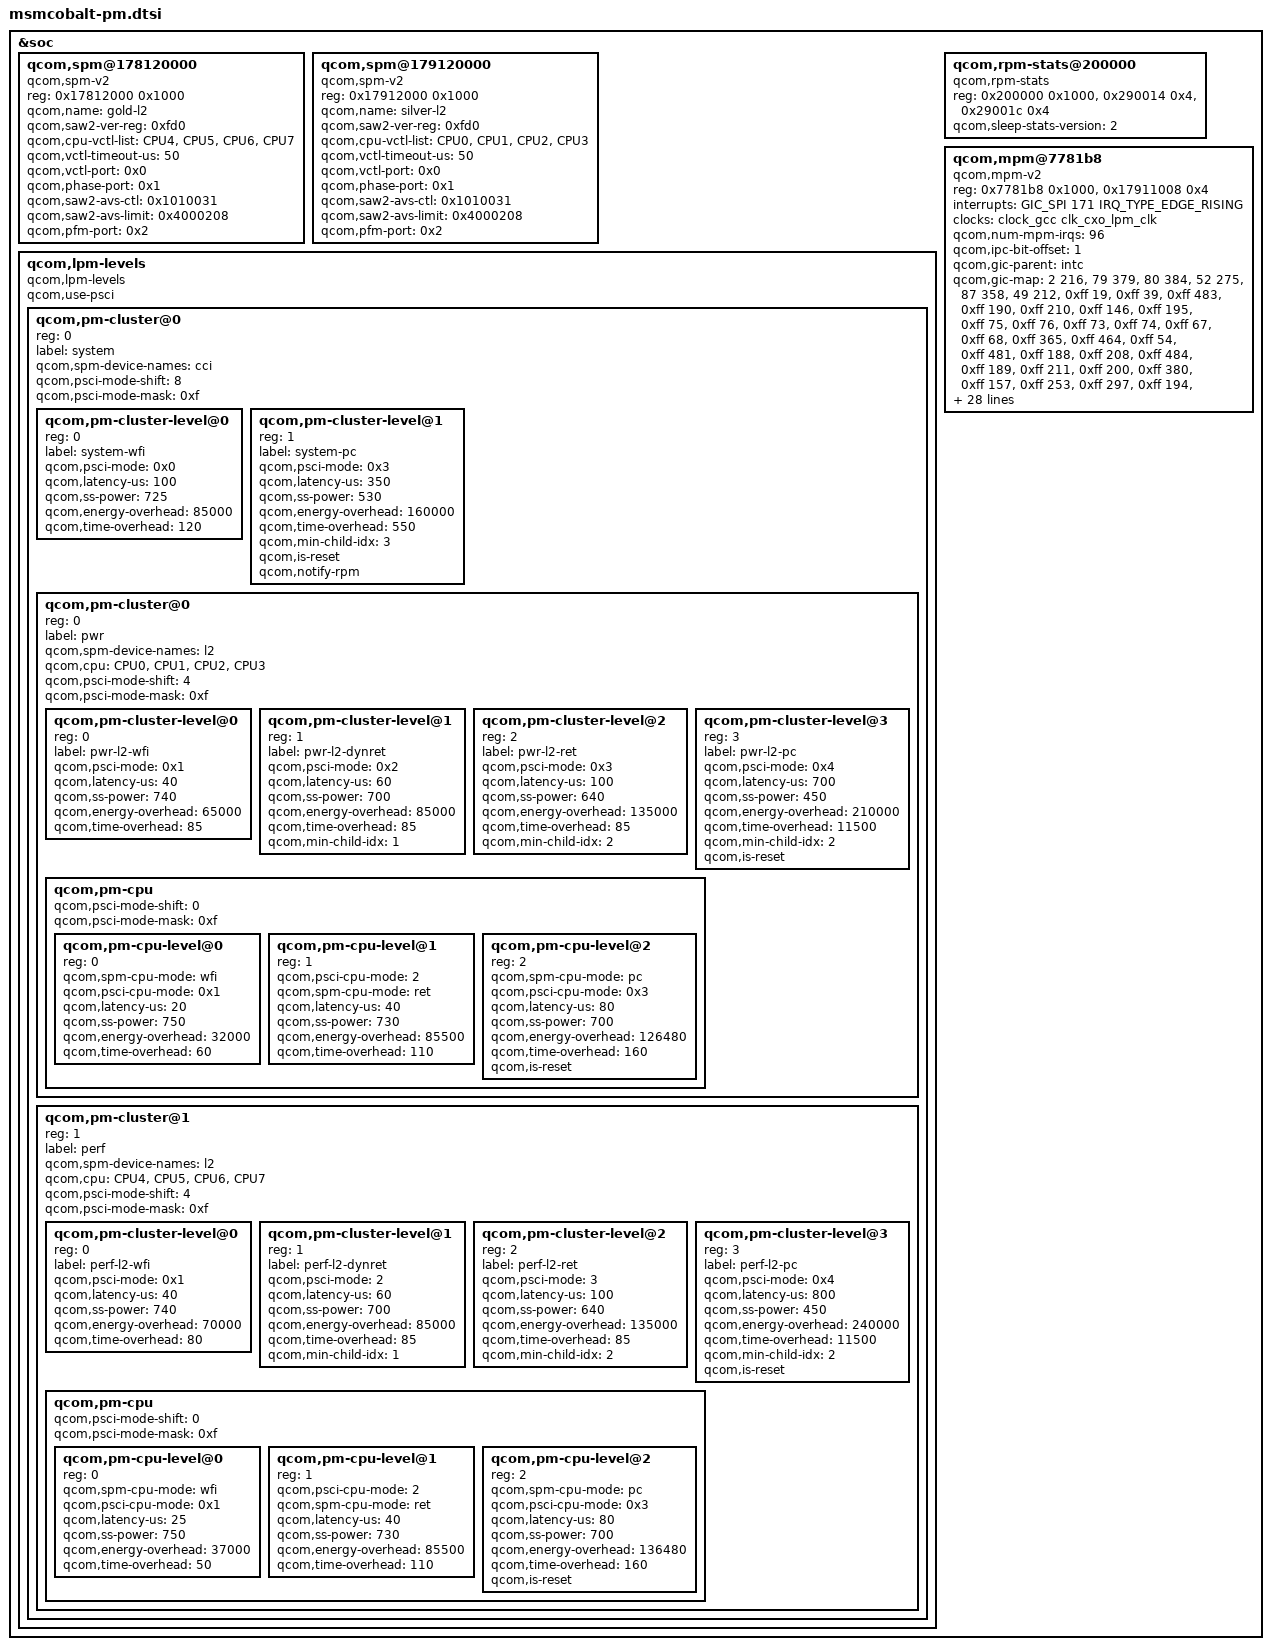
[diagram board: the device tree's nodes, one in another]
/* Copyright (c) 2016, The Linux Foundation. All rights reserved.
 *
 * This program is free software; you can redistribute it and/or modify
 * it under the terms of the GNU General Public License version 2 and
 * only version 2 as published by the Free Software Foundation.
 *
 * This program is distributed in the hope that it will be useful,
 * but WITHOUT ANY WARRANTY; without even the implied warranty of
 * MERCHANTABILITY or FITNESS FOR A PARTICULAR PURPOSE.  See the
 * GNU General Public License for more details.
 */
#include <dt-bindings/interrupt-controller/arm-gic.h>

&soc {
	qcom,spm@178120000 {
		compatible = "qcom,spm-v2";
		#address-cells = <1>;
		#size-cells = <1>;
		reg = <0x17812000 0x1000>;
		qcom,name = "gold-l2"; /* Gold L2 SAW */
		qcom,saw2-ver-reg = <0xfd0>;
		qcom,cpu-vctl-list = <&CPU4 &CPU5 &CPU6 &CPU7>;
		qcom,vctl-timeout-us = <50>;
		qcom,vctl-port = <0x0>;
		qcom,phase-port = <0x1>;
		qcom,saw2-avs-ctl = <0x1010031>;
		qcom,saw2-avs-limit = <0x4000208>;
		qcom,pfm-port = <0x2>;
	};

	qcom,spm@179120000 {
		compatible = "qcom,spm-v2";
		#address-cells = <1>;
		#size-cells = <1>;
		reg = <0x17912000 0x1000>;
		qcom,name = "silver-l2"; /* Silver L2 SAW */
		qcom,saw2-ver-reg = <0xfd0>;
		qcom,cpu-vctl-list = <&CPU0 &CPU1 &CPU2 &CPU3>;
		qcom,vctl-timeout-us = <50>;
		qcom,vctl-port = <0x0>;
		qcom,phase-port = <0x1>;
		qcom,saw2-avs-ctl = <0x1010031>;
		qcom,saw2-avs-limit = <0x4000208>;
		qcom,pfm-port = <0x2>;
	};

	qcom,lpm-levels {
		compatible = "qcom,lpm-levels";
		qcom,use-psci;
		#address-cells = <1>;
		#size-cells = <0>;
		qcom,pm-cluster@0 {
			reg = <0>;
			#address-cells = <1>;
			#size-cells = <0>;
			label = "system";
			qcom,spm-device-names = "cci";
			qcom,psci-mode-shift = <8>;
			qcom,psci-mode-mask = <0xf>;

			qcom,pm-cluster-level@0{
				reg = <0>;
				label = "system-wfi";
				qcom,psci-mode = <0x0>;
				qcom,latency-us = <100>;
				qcom,ss-power = <725>;
				qcom,energy-overhead = <85000>;
				qcom,time-overhead = <120>;
			};

			qcom,pm-cluster-level@1{ /* E3 */
				reg = <1>;
				label = "system-pc";
				qcom,psci-mode = <0x3>;
				qcom,latency-us = <350>;
				qcom,ss-power = <530>;
				qcom,energy-overhead = <160000>;
				qcom,time-overhead = <550>;
				qcom,min-child-idx = <3>;
				qcom,is-reset;
				qcom,notify-rpm;
			};

			qcom,pm-cluster@0{
				reg = <0>;
				#address-cells = <1>;
				#size-cells = <0>;
				label = "pwr";
				qcom,spm-device-names = "l2";
				qcom,cpu = <&CPU0 &CPU1 &CPU2 &CPU3>;
				qcom,psci-mode-shift = <4>;
				qcom,psci-mode-mask = <0xf>;

				qcom,pm-cluster-level@0{ /* D1 */
					reg = <0>;
					label = "pwr-l2-wfi";
					qcom,psci-mode = <0x1>;
					qcom,latency-us = <40>;
					qcom,ss-power = <740>;
					qcom,energy-overhead = <65000>;
					qcom,time-overhead = <85>;
				};
				qcom,pm-cluster-level@1{ /* D2D */
					reg = <1>;
					label = "pwr-l2-dynret";
					qcom,psci-mode = <0x2>;
					qcom,latency-us = <60>;
					qcom,ss-power = <700>;
					qcom,energy-overhead = <85000>;
					qcom,time-overhead = <85>;
					qcom,min-child-idx = <1>;
				};

				qcom,pm-cluster-level@2{ /* D2E */
					reg = <2>;
					label = "pwr-l2-ret";
					qcom,psci-mode = <0x3>;
					qcom,latency-us = <100>;
					qcom,ss-power = <640>;
					qcom,energy-overhead = <135000>;
					qcom,time-overhead = <85>;
					qcom,min-child-idx = <2>;
				};

				qcom,pm-cluster-level@3{ /* D4 */
					reg = <3>;
					label = "pwr-l2-pc";
					qcom,psci-mode = <0x4>;
					qcom,latency-us = <700>;
					qcom,ss-power = <450>;
					qcom,energy-overhead = <210000>;
					qcom,time-overhead = <11500>;
					qcom,min-child-idx = <2>;
					qcom,is-reset;
				};

				qcom,pm-cpu {
					#address-cells = <1>;
					#size-cells = <0>;
					qcom,psci-mode-shift = <0>;
					qcom,psci-mode-mask = <0xf>;

					qcom,pm-cpu-level@0 { /* C1 */
						reg = <0>;
						qcom,spm-cpu-mode = "wfi";
						qcom,psci-cpu-mode = <0x1>;
						qcom,latency-us = <20>;
						qcom,ss-power = <750>;
						qcom,energy-overhead = <32000>;
						qcom,time-overhead = <60>;
					};

					qcom,pm-cpu-level@1 { /* C2D */
						reg = <1>;
						qcom,psci-cpu-mode = <2>;
						qcom,spm-cpu-mode = "ret";
						qcom,latency-us = <40>;
						qcom,ss-power = <730>;
						qcom,energy-overhead = <85500>;
						qcom,time-overhead = <110>;
					};

					qcom,pm-cpu-level@2 {  /* C3 */
						reg = <2>;
						qcom,spm-cpu-mode = "pc";
						qcom,psci-cpu-mode = <0x3>;
						qcom,latency-us = <80>;
						qcom,ss-power = <700>;
						qcom,energy-overhead = <126480>;
						qcom,time-overhead = <160>;
						qcom,is-reset;
					};
				};
			};

			qcom,pm-cluster@1{
				reg = <1>;
				#address-cells = <1>;
				#size-cells = <0>;
				label = "perf";
				qcom,spm-device-names = "l2";
				qcom,cpu = <&CPU4 &CPU5 &CPU6 &CPU7>;
				qcom,psci-mode-shift = <4>;
				qcom,psci-mode-mask = <0xf>;

				qcom,pm-cluster-level@0{  /* D1 */
					reg = <0>;
					label = "perf-l2-wfi";
					qcom,psci-mode = <0x1>;
					qcom,latency-us = <40>;
					qcom,ss-power = <740>;
					qcom,energy-overhead = <70000>;
					qcom,time-overhead = <80>;
				};

				qcom,pm-cluster-level@1{ /* D2D */
					reg = <1>;
					label = "perf-l2-dynret";
					qcom,psci-mode = <2>;
					qcom,latency-us = <60>;
					qcom,ss-power = <700>;
					qcom,energy-overhead = <85000>;
					qcom,time-overhead = <85>;
					qcom,min-child-idx = <1>;
				};

				qcom,pm-cluster-level@2{ /* D2E */
					reg = <2>;
					label = "perf-l2-ret";
					qcom,psci-mode = <3>;
					qcom,latency-us = <100>;
					qcom,ss-power = <640>;
					qcom,energy-overhead = <135000>;
					qcom,time-overhead = <85>;
					qcom,min-child-idx = <2>;
				};

				qcom,pm-cluster-level@3{ /* D4 */
					reg = <3>;
					label = "perf-l2-pc";
					qcom,psci-mode = <0x4>;
					qcom,latency-us = <800>;
					qcom,ss-power = <450>;
					qcom,energy-overhead = <240000>;
					qcom,time-overhead = <11500>;
					qcom,min-child-idx = <2>;
					qcom,is-reset;
				};

				qcom,pm-cpu {
					#address-cells = <1>;
					#size-cells = <0>;
					qcom,psci-mode-shift = <0>;
					qcom,psci-mode-mask = <0xf>;

					qcom,pm-cpu-level@0 { /* C1 */
						reg = <0>;
						qcom,spm-cpu-mode = "wfi";
						qcom,psci-cpu-mode = <0x1>;
						qcom,latency-us = <25>;
						qcom,ss-power = <750>;
						qcom,energy-overhead = <37000>;
						qcom,time-overhead = <50>;
					};

					qcom,pm-cpu-level@1 { /* C2D */
						reg = <1>;
						qcom,psci-cpu-mode = <2>;
						qcom,spm-cpu-mode = "ret";
						qcom,latency-us = <40>;
						qcom,ss-power = <730>;
						qcom,energy-overhead = <85500>;
						qcom,time-overhead = <110>;
					};

					qcom,pm-cpu-level@2 { /* C3 */
						reg = <2>;
						qcom,spm-cpu-mode = "pc";
						qcom,psci-cpu-mode = <0x3>;
						qcom,latency-us = <80>;
						qcom,ss-power = <700>;
						qcom,energy-overhead = <136480>;
						qcom,time-overhead = <160>;
						qcom,is-reset;
					};
				};
			};
		};
	};

	qcom,rpm-stats@200000 {
		compatible = "qcom,rpm-stats";
		reg = <0x200000 0x1000>,
			<0x290014 0x4>,
			<0x29001c 0x4>;
		reg-names = "phys_addr_base",
			"offset_addr",
			"heap_phys_addrbase";
		qcom,sleep-stats-version = <2>;
	};

	qcom,mpm@7781b8 {
		compatible = "qcom,mpm-v2";
		reg = <0x7781b8 0x1000>, /* MSM_RPM_MPM_BASE 4K */
		    <0x17911008 0x4>;   /* MSM_APCS_GCC_BASE 4K */
		reg-names = "vmpm", "ipc";
		interrupts = <GIC_SPI 171 IRQ_TYPE_EDGE_RISING>;
		clocks = <&clock_gcc clk_cxo_lpm_clk>;
		clock-names = "xo";
		qcom,num-mpm-irqs = <96>;

		qcom,ipc-bit-offset = <1>;

		qcom,gic-parent = <&intc>;
		qcom,gic-map = <2 216>, /* tsens_upper_lower_int */
			<79 379>,   /* qusb2phy_dmse_hv_prim */
			<80 384>,   /* qusb2phy_dmse_hv_sec */
			<52 275>,   /* qmp_usb3_lfps_rxterm_irq */
			<87 358>,   /* ee0_krait_hlos_spmi_periph_irq */
			<49 212>,   /* usb30_power_event_irq */
			<0xff  19>, /* arch_timer */
			<0xff  39>, /* arch_mem_timer */
			<0xff  483>, /* smp2p */
			<0xff  190>, /* smp2p */
			<0xff  210>, /* smp2p */
			<0xff  146>, /* msm_serial0 */
			<0xff  195>, /* ngd_slim_irq */
			<0xff  75>, /* ARM64 */
			<0xff  76>, /* ARM64 */
			<0xff  73>, /* ARM64 */
			<0xff  74>, /* ARM64 */
			<0xff  67>, /* OSM */
			<0xff  68>, /* OSM */
			<0xff  365>, /* ipa */
			<0xff  464>, /* gsi */
			<0xff  54>, /* gladiator-error */
			<0xff  481>, /* qcom,smd-modem */
			<0xff  188>, /* qcom,smd-adsp */
			<0xff  208>, /* qcom,smd-dsps */
			<0xff  484>, /* qcom,glink-smem-native-xprt-modem */
			<0xff  189>, /* qcom,glink-smem-native-xprt-adsp */
			<0xff  211>, /* qcom,glink-smem-native-xprt-dsps */
			<0xff  200>, /* qcom,glink-smem-native-xprt-rpm */
			<0xff  380>, /* qcom,glink-mailbox-xprt-spss */
			<0xff  157>, /* mmc0 */
			<0xff  253>, /* c0a4900.sdhci */
			<0xff  297>, /* ufshcd */
			<0xff  194>, /* adsp */
			<0xff  480>, /* modem */
			<0xff  490>, /* tsens_interrupt */
			<0xff  477>, /* tsens_critical_interrupt */
			<0xff  462>, /* tsens_critical_interrupt */
			<0xff  38>, /* lmh-interrupt */
			<0xff  422>, /* slpi */
			<0xff  35>, /* apps_wdog_bark */
			<0xff  22>, /* arm-pmu */
			<0xff  317>, /* cpr3 */
			<0xff  203>, /* 7781b8.qcom,mpm */
			<0xff  261>, /* arm-smmu */
			<0xff  263>, /* arm-smmu */
			<0xff  405>, /* arm-smmu-context-fault */
			<0xff  258>, /* arm-smmu-context-fault */
			<0xff  425>, /* arm-smmu-context-fault */
			<0xff  426>, /* arm-smmu-context-fault */
			<0xff  427>, /* arm-smmu-context-fault */
			<0xff  428>, /* arm-smmu-context-fault */
			<0xff  429>, /* arm-smmu-context-fault */
			<0xff  430>, /* arm-smmu-context-fault */
			<0xff  431>, /* arm-smmu-context-fault */
			<0xff  295>, /* arm-smmu-context-fault */
			<0xff  298>, /* arm-smmu-context-fault */
			<0xff  299>, /* arm-smmu-context-fault */
			<0xff  300>, /* arm-smmu-context-fault */
			<0xff  276>, /* arm-smmu-context-fault */
			<0xff  277>, /* arm-smmu-context-fault */
			<0xff  361>, /* arm-smmu-context-fault */
			<0xff  362>, /* arm-smmu-"ontext-fault */
			<0xff  110>, /* csiphy */
			<0xff  111>, /* csiphy */
			<0xff  112>, /* csiphy */
			<0xff  328>, /* csid */
			<0xff  329>, /* csid */
			<0xff  330>, /* csid */
			<0xff  331>, /* csid */
			<0xff  326>, /*  */
			<0xff  341>, /* ispif */
			<0xff  346>, /* vfe */
			<0xff  347>, /* vfe */
			<0xff  327>, /* cci */
			<0xff  319>, /* msm_vidc */
			<0xff  332>, /* kgsl-3d0 */
			<0xff  115>, /* MDSS */
			<0xff  131>, /* i2c-msm-v2-irq */
			<0xff  163>, /* dwc3 */
			<0xff  240>, /* tlmm */
			<0xff  310>, /* pcie20_global_int */
			<0xff  323>, /* lpass_slimbus1_core_ee1_irq */
			<0xff  437>, /* pcie20_0_int_msi_dev0 */
			<0xff  196>, /* lpass_aud_slimbus_bam_ee1_irq */
			<0xff  215>, /* o_bimc_intr */
			<0xff  280>, /* pcie20_intd */
			<0xff  324>, /* lpass_qca_slimbus_bam_ee1_irq */
			<0xff  432>, /* smmu_Cirpt[8] */
			<0xff  433>, /* smmu_Cirpt[9] */
			<0xff  461>; /* o_ocimem_nonsec_irq */

		qcom,gpio-parent = <&tlmm>;
		qcom,gpio-map = <3  1>,
			<4  5>,
			<5  9>,
			<6  11>,
			<7  66>,
			<8  22>,
			<9  24>,
			<10  26>,
			<11  34>,
			<12  36>,
			<13  37>, /* PCIe0 */
			<14  38>,
			<15  40>,
			<16  42>,
			<17  46>,
			<18  50>,
			<19  53>,
			<20  54>,
			<21  56>,
			<22  57>,
			<23  58>,
			<24  59>,
			<25  60>,
			<26  61>,
			<27  62>,
			<28  63>,
			<29  64>,
			<30  71>,
			<31  73>,
			<32  77>,
			<33  78>,
			<34  79>,
			<35  80>,
			<36  82>,
			<37  86>,
			<38  91>,
			<39  92>,
			<40  95>,
			<41  97>,
			<42  101>,
			<43  104>,
			<44  106>,
			<45  108>,
			<46  112>,
			<47  113>,
			<48  110>,
			<50  127>,
			<51  115>,
			<54  116>, /* PCIe2 */
			<55  117>,
			<56  118>,
			<57  119>,
			<58  120>,
			<59  121>,
			<60  122>,
			<61  123>,
			<62  124>,
			<63  125>,
			<64  126>,
			<65  129>,
			<66  131>,
			<67  132>, /* PCIe1 */
			<68  133>,
			<69  145>;
	};
};
